AUTOSAR XML (schema 4.0)
standard types defined: float32, float64, sint16, sint32, sint8, uint16, uint32, uint8, void, boolean
package /ImplDataTypes
  8 x impl type, all with category=TYPE_REFERENCE, type-emitter=RTE:
    IOSensorPositionReadingType: implementation-data-type=uint8
    IOWeightSensorReadingType: implementation-data-type=uint16
    MultiStateBtnType: implementation-data-type=uint8
    SeatCtrlBtns: implementation-data-type=SeatCtrlData
    SeatModeBtn: implementation-data-type=uint8
    SensorPositionType: implementation-data-type=uint8
    SensorWeightType: implementation-data-type=uint8
    StepMotorStepType: implementation-data-type=void
package /MappingSets
  data type mapping set MappingSet: mode-request-type-map{implementation-data-type=uint8, mode-group=SeatCtrlMode}
package /PortInterfaces/ClientServer
  8 x client server interface:
    CsIf_HeightMotor
      operation Opr_HeightMotorMove
        arg Step: type=StepMotorStepType, direction=IN
    CsIf_IOGetSensorPosition
      operation Opr_IOGet
        arg position: type=IOSensorPositionReadingType, direction=OUT
    CsIf_IOGetSensorWeight
      operation Opr_IOGet
        arg weight: type=IOWeightSensorReadingType, direction=OUT
    CsIf_IOSetMotor
      operation Opr_IOSetBackward
      operation Opr_IOSetForward
    CsIf_InclineMotor
      operation Opr_InclineMotorMove
        arg Step: type=StepMotorStepType, direction=IN
    CsIf_PositionSensor
      operation Opr_GetPosition
        arg position: type=SensorPositionType, direction=OUT
    CsIf_SlideMotor
      operation Opr_SlideMotorMove
        arg Step: type=StepMotorStepType, direction=IN
    CsIf_WeightSensor
      operation Opr_GetWeight
        arg weight: type=SensorWeightType, direction=OUT
package /PortInterfaces/ModeSwitch
  mode switch interface MsIf_SeatCtrlMode
    mode group SeatCtrlMode: type=SeatCtrlMode
  mode declaration group SeatCtrlMode: category=ALPHABETIC_ORDER, initial-mode=INIT, on-transition-value=255
    mode AUTO
    mode INIT
    mode MANUAL
package /PortInterfaces/SenderReceiver
  sender receiver interface SrIf_SeatCtrlBtns
    data HeightBtnState: type=MultiStateBtnType
    data InclineBtnState: type=MultiStateBtnType
    data SlideBtnState: type=MultiStateBtnType
  sender receiver interface SrIf_SeatCtrlData
    data Height: type=uint8
    data Incline: type=uint8
    data Slide: type=uint8
  sender receiver interface SrIf_SeatModeBtn
    data DE_SeatModeBtn: type=SeatModeBtn
package /SoftwareComponents
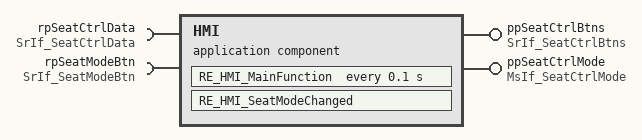
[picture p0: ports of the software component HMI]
  application sw component type HMI
    provide port ppSeatCtrlBtns: provided-interface=SrIf_SeatCtrlBtns
    provide port ppSeatCtrlMode: provided-interface=MsIf_SeatCtrlMode
    require port rpSeatCtrlData: required-interface=SrIf_SeatCtrlData
    require port rpSeatModeBtn: required-interface=SrIf_SeatModeBtn
    behavior Ibhv_HMI: data-type-mapping=MappingSet, handle-termination-and-restart=NO-SUPPORT
      data received event DRE_rpSeatModeBtn_DE_SeatModeBtn: start-on-event=RE_HMI_SeatModeChanged, data=rpSeatModeBtn.DE_SeatModeBtn
      timing event TE_RE_HMI_MainFunction_100ms: start-on-event=RE_HMI_MainFunction, period=0.1
      runnable RE_HMI_MainFunction
        data-receive-point-by-arguments:
          access DRP_rpSeatCtrlData_Height: accessed-variable=rpSeatCtrlData.Height
          access DRP_rpSeatCtrlData_Incline: accessed-variable=rpSeatCtrlData.Incline
          access DRP_rpSeatCtrlData_Slide: accessed-variable=rpSeatCtrlData.Slide
        data-send-points:
          access DSP_ppSeatCtrlBtns_HeightBtnState: accessed-variable=ppSeatCtrlBtns.HeightBtnState
          access DSP_ppSeatCtrlBtns_InclineBtnState: accessed-variable=ppSeatCtrlBtns.InclineBtnState
          access DSP_ppSeatCtrlBtns_SlideBtnState: accessed-variable=ppSeatCtrlBtns.SlideBtnState
      runnable RE_HMI_SeatModeChanged
        data-receive-point-by-arguments:
          access DRP_rpSeatModeBtn_DE_SeatModeBtn: accessed-variable=rpSeatModeBtn.DE_SeatModeBtn
        mode switch point MSP_ppSeatCtrlMode_ppSeatCtrlMode: mode-group=ppSeatCtrlMode.SeatCtrlMode
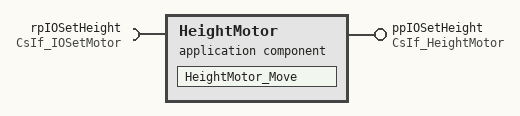
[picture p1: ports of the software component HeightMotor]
  application sw component type HeightMotor
    provide port ppIOSetHeight: provided-interface=CsIf_HeightMotor
    require port rpIOSetHeight: required-interface=CsIf_IOSetMotor
    behavior Ibhv_HeightMotor: data-type-mapping=MappingSet, handle-termination-and-restart=NO-SUPPORT
      operation invoked event OIE_ppIOSetHeight_Opr_HeightMotorMove: start-on-event=HeightMotor_Move, operation=ppIOSetHeight.Opr_HeightMotorMove
      runnable HeightMotor_Move
        sync call SCP_rpIOSetHeight_Opr_IOSetBackward: operation=rpIOSetHeight.Opr_IOSetBackward, timeout=0.0
        sync call SCP_rpIOSetHeight_Opr_IOSetForward: operation=rpIOSetHeight.Opr_IOSetForward, timeout=0.0
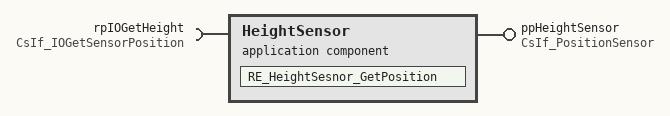
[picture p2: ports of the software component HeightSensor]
  application sw component type HeightSensor
    provide port ppHeightSensor: provided-interface=CsIf_PositionSensor
    require port rpIOGetHeight: required-interface=CsIf_IOGetSensorPosition
    behavior Ibhv_HeightSensor: data-type-mapping=MappingSet, handle-termination-and-restart=NO-SUPPORT
      operation invoked event OIE_ppHeightSensor_Opr_GetPosition: start-on-event=RE_HeightSesnor_GetPosition, operation=ppHeightSensor.Opr_GetPosition
      runnable RE_HeightSesnor_GetPosition
        sync call SCP_rpIOGetHeight_Opr_IOGet: operation=rpIOGetHeight.Opr_IOGet, timeout=0.0
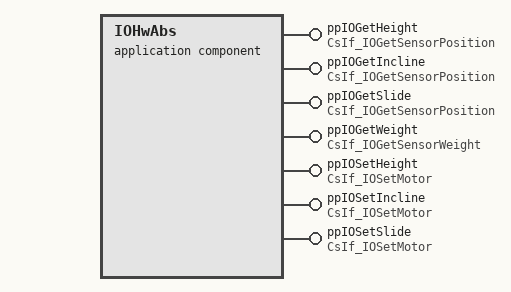
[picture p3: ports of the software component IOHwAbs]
  application sw component type IOHwAbs
    7 x provide port:
      ppIOGetHeight: provided-interface=CsIf_IOGetSensorPosition
      ppIOGetIncline: provided-interface=CsIf_IOGetSensorPosition
      ppIOGetSlide: provided-interface=CsIf_IOGetSensorPosition
      ppIOGetWeight: provided-interface=CsIf_IOGetSensorWeight
      ppIOSetHeight: provided-interface=CsIf_IOSetMotor
      ppIOSetIncline: provided-interface=CsIf_IOSetMotor
      ppIOSetSlide: provided-interface=CsIf_IOSetMotor
    behavior Ibhv_IOHwAbs: data-type-mapping=MappingSet, handle-termination-and-restart=NO-SUPPORT
      10 x operation invoked event:
        OIE_ppIOGetHeight_Opr_IOGet: start-on-event=RE_IOHwAbs_ECUGet_Height, operation=ppIOGetHeight.Opr_IOGet
        OIE_ppIOGetIncline_Opr_IOGet: start-on-event=RE_IOHwAbs_ECUGet_Incline, operation=ppIOGetIncline.Opr_IOGet
        OIE_ppIOGetSlide_Opr_IOGet: start-on-event=RE_IOHwAbs_ECUGet_Slide, operation=ppIOGetSlide.Opr_IOGet
        OIE_ppIOGetWeight_Opr_IOGet: start-on-event=RE_IOHwAbs_ECUGet_Weight, operation=ppIOGetWeight.Opr_IOGet
        OIE_ppIOSetHeight_Opr_IOSetBackward: start-on-event=RE_IOHwAbs_ECUSetBackward_Height, operation=ppIOSetHeight.Opr_IOSetBackward
        OIE_ppIOSetHeight_Opr_IOSetForward: start-on-event=RE_IOHwAbs_ECUSetForward_Height, operation=ppIOSetHeight.Opr_IOSetForward
        OIE_ppIOSetIncline_Opr_IOSetBackward: start-on-event=RE_IOHwAbs_ECUSetBackward_Incline, operation=ppIOSetIncline.Opr_IOSetBackward
        OIE_ppIOSetIncline_Opr_IOSetForward: start-on-event=RE_IOHwAbs_ECUSetForward_Incline, operation=ppIOSetIncline.Opr_IOSetForward
        OIE_ppIOSetSlide_Opr_IOSetBackward: start-on-event=RE_IOHwAbs_ECUSetBackward_Slide, operation=ppIOSetSlide.Opr_IOSetBackward
        OIE_ppIOSetSlide_Opr_IOSetForward: start-on-event=RE_IOHwAbs_ECUSetForward_Slide, operation=ppIOSetSlide.Opr_IOSetForward
      10 x runnable:
        RE_IOHwAbs_ECUGet_Height
        RE_IOHwAbs_ECUGet_Incline
        RE_IOHwAbs_ECUGet_Slide
        RE_IOHwAbs_ECUGet_Weight
        RE_IOHwAbs_ECUSetBackward_Height
        RE_IOHwAbs_ECUSetBackward_Incline
        RE_IOHwAbs_ECUSetBackward_Slide
        RE_IOHwAbs_ECUSetForward_Height
        RE_IOHwAbs_ECUSetForward_Incline
        RE_IOHwAbs_ECUSetForward_Slide
  10 x swc implementation, all with programming-language=C, sw-version=1.0.0, vendor-id=255:
    Impl_HMI: behavior=Ibhv_HMI
      code-descriptors:
        code Code: artifact-descriptors=autosar-engineering-object={short-label=SWC.c, category=SWSRC}
      resource consumption ResourceConsumption
    Impl_HeightMotor: behavior=Ibhv_HeightMotor
      code-descriptors:
        code Code: artifact-descriptors=autosar-engineering-object={short-label=SWC.c, category=SWSRC}
      resource consumption ResourceConsumption
    Impl_HeightSensor: behavior=Ibhv_HeightSensor
      code-descriptors:
        code Code: artifact-descriptors=autosar-engineering-object={short-label=SWC.c, category=SWSRC}
      resource consumption ResourceConsumption
    Impl_IOHwAbs: behavior=Ibhv_IOHwAbs
      code-descriptors:
        code Code: artifact-descriptors=autosar-engineering-object={short-label=SWC.c, category=SWSRC}
      resource consumption ResourceConsumption
    Impl_InclineMotor: behavior=Ibhv_InclineMotor
      code-descriptors:
        code Code: artifact-descriptors=autosar-engineering-object={short-label=SWC.c, category=SWSRC}
      resource consumption ResourceConsumption
    Impl_InclineSensor: behavior=Ibhv_InclineSensor
      code-descriptors:
        code Code: artifact-descriptors=autosar-engineering-object={short-label=SWC.c, category=SWSRC}
      resource consumption ResourceConsumption
    Impl_SeatManager: behavior=Ibhv_SeatManager
      code-descriptors:
        code Code: artifact-descriptors=autosar-engineering-object={short-label=SWC.c, category=SWSRC}
      resource consumption ResourceConsumption
    Impl_SlideMotor: behavior=Ibhv_SlideMotor
      code-descriptors:
        code Code: artifact-descriptors=autosar-engineering-object={short-label=SWC.c, category=SWSRC}
      resource consumption ResourceConsumption
    Impl_SlideSensor: behavior=Ibhv_SlideSensor
      code-descriptors:
        code Code: artifact-descriptors=autosar-engineering-object={short-label=SWC.c, category=SWSRC}
      resource consumption ResourceConsumption
    Impl_WeightSensor: behavior=Ibhv_WeightSensor
      code-descriptors:
        code Code: artifact-descriptors=autosar-engineering-object={short-label=SWC.c, category=SWSRC}
      resource consumption ResourceConsumption
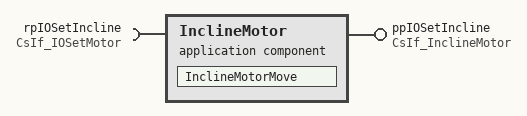
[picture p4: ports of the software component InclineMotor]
  application sw component type InclineMotor
    provide port ppIOSetIncline: provided-interface=CsIf_InclineMotor
    require port rpIOSetIncline: required-interface=CsIf_IOSetMotor
    behavior Ibhv_InclineMotor: data-type-mapping=MappingSet, handle-termination-and-restart=NO-SUPPORT
      operation invoked event OIE_ppIOSetIncline_Opr_InclineMotorMove: start-on-event=InclineMotorMove, operation=ppIOSetIncline.Opr_InclineMotorMove
      runnable InclineMotorMove
        sync call SCP_rpIOSetIncline_Opr_IOSetBackward: operation=rpIOSetIncline.Opr_IOSetBackward, timeout=0.0
        sync call SCP_rpIOSetIncline_Opr_IOSetForward: operation=rpIOSetIncline.Opr_IOSetForward, timeout=0.0
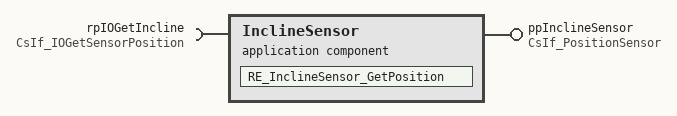
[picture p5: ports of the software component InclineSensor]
  application sw component type InclineSensor
    provide port ppInclineSensor: provided-interface=CsIf_PositionSensor
    require port rpIOGetIncline: required-interface=CsIf_IOGetSensorPosition
    behavior Ibhv_InclineSensor: data-type-mapping=MappingSet, handle-termination-and-restart=NO-SUPPORT
      operation invoked event OIE_ppInclineSensor_Opr_GetPosition: start-on-event=RE_InclineSensor_GetPosition, operation=ppInclineSensor.Opr_GetPosition
      runnable RE_InclineSensor_GetPosition
        sync call SCP_rpIOGetIncline_Opr_IOGet: operation=rpIOGetIncline.Opr_IOGet, timeout=0.0
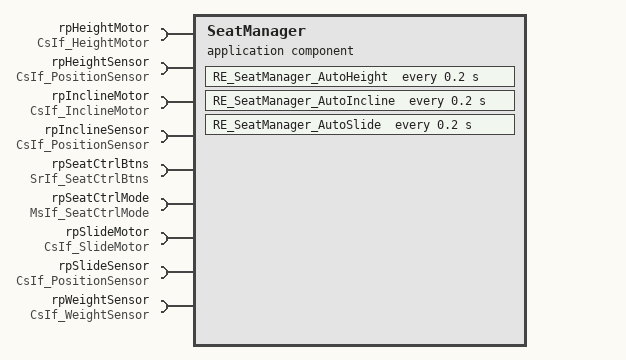
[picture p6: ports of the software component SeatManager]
  application sw component type SeatManager
    9 x require port:
      rpHeightMotor: required-interface=CsIf_HeightMotor
      rpHeightSensor: required-interface=CsIf_PositionSensor
      rpInclineMotor: required-interface=CsIf_InclineMotor
      rpInclineSensor: required-interface=CsIf_PositionSensor
      rpSeatCtrlBtns: required-interface=SrIf_SeatCtrlBtns
      rpSeatCtrlMode: required-interface=MsIf_SeatCtrlMode
      rpSlideMotor: required-interface=CsIf_SlideMotor
      rpSlideSensor: required-interface=CsIf_PositionSensor
      rpWeightSensor: required-interface=CsIf_WeightSensor
    behavior Ibhv_SeatManager: data-type-mapping=MappingSet, handle-termination-and-restart=NO-SUPPORT
      data received event DRE_rpSeatCtrlBtns_HeightBtnState: start-on-event=RE_SeatManger_SetHeight, data=rpSeatCtrlBtns.HeightBtnState
      data received event DRE_rpSeatCtrlBtns_InclineBtnState: start-on-event=RE_SeatManager_SetIncline, data=rpSeatCtrlBtns.InclineBtnState
      data received event DRE_rpSeatCtrlBtns_SlideBtnState: start-on-event=RE_SeatManager_SetSlide, data=rpSeatCtrlBtns.SlideBtnState
      timing event TE_RE_SeatManager_AutoHeight_200ms: start-on-event=RE_SeatManager_AutoHeight, period=0.2
      timing event TE_RE_SeatManager_AutoIncline_200ms: start-on-event=RE_SeatManager_AutoIncline, period=0.2
      timing event TE_RE_SeatManager_AutoSlide_200ms: start-on-event=RE_SeatManager_AutoSlide, period=0.2
      6 x runnable:
        RE_SeatManager_AutoHeight
          sync call SCP_rpHeightMotor_Opr_HeightMotorMove: operation=rpHeightMotor.Opr_HeightMotorMove, timeout=0.0
          sync call SCP_rpHeightSensor_Opr_GetPosition: operation=rpHeightSensor.Opr_GetPosition, timeout=0.0
          sync call SCP_rpWeightSensor_Opr_GetWeight: operation=rpWeightSensor.Opr_GetWeight, timeout=0.0
        RE_SeatManager_AutoIncline
          sync call SCP_rpInclineMotor_Opr_InclineMotorMove: operation=rpInclineMotor.Opr_InclineMotorMove, timeout=0.0
          sync call SCP_rpInclineSensor_Opr_GetPosition: operation=rpInclineSensor.Opr_GetPosition, timeout=0.0
          sync call SCP_rpWeightSensor_Opr_GetWeight: operation=rpWeightSensor.Opr_GetWeight, timeout=0.0
        RE_SeatManager_AutoSlide
          sync call SCP_rpSlideMotor_Opr_SlideMotorMove: operation=rpSlideMotor.Opr_SlideMotorMove, timeout=0.0
          sync call SCP_rpSlideSensor_Opr_GetPosition: operation=rpSlideSensor.Opr_GetPosition, timeout=0.0
          sync call SCP_rpWeightSensor_Opr_GetWeight: operation=rpWeightSensor.Opr_GetWeight, timeout=0.0
        RE_SeatManager_SetIncline
          data-receive-point-by-arguments:
            access DRP_rpSeatCtrlBtns_InclineBtnState: accessed-variable=rpSeatCtrlBtns.InclineBtnState
          sync call SCP_rpInclineMotor_Opr_InclineMotorMove: operation=rpInclineMotor.Opr_InclineMotorMove, timeout=0.0
        RE_SeatManager_SetSlide
          data-receive-point-by-arguments:
            access DRP_rpSeatCtrlBtns_SlideBtnState: accessed-variable=rpSeatCtrlBtns.SlideBtnState
          sync call SCP_rpSlideMotor_Opr_SlideMotorMove: operation=rpSlideMotor.Opr_SlideMotorMove, timeout=0.0
        RE_SeatManger_SetHeight
          data-receive-point-by-arguments:
            access DRP_rpSeatCtrlBtns_HeightBtnState: accessed-variable=rpSeatCtrlBtns.HeightBtnState
          sync call SCP_rpHeightMotor_Opr_HeightMotorMove: operation=rpHeightMotor.Opr_HeightMotorMove, timeout=0.0
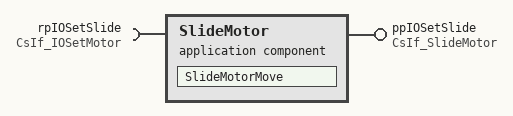
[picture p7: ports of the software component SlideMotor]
  application sw component type SlideMotor
    provide port ppIOSetSlide: provided-interface=CsIf_SlideMotor
    require port rpIOSetSlide: required-interface=CsIf_IOSetMotor
    behavior Ibhv_SlideMotor: data-type-mapping=MappingSet, handle-termination-and-restart=NO-SUPPORT
      operation invoked event OIE_ppIOSetSlide_Opr_SlideMotorMove: start-on-event=SlideMotorMove, operation=ppIOSetSlide.Opr_SlideMotorMove
      runnable SlideMotorMove
        sync call SCP_rpIOSetSlide_Opr_IOSetBackward: operation=rpIOSetSlide.Opr_IOSetBackward, timeout=0.0
        sync call SCP_rpIOSetSlide_Opr_IOSetForward: operation=rpIOSetSlide.Opr_IOSetForward, timeout=0.0
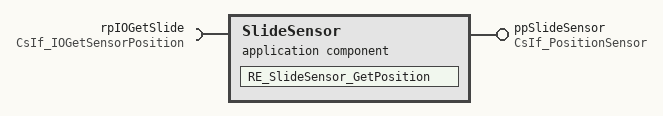
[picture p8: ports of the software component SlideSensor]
  application sw component type SlideSensor
    provide port ppSlideSensor: provided-interface=CsIf_PositionSensor
    require port rpIOGetSlide: required-interface=CsIf_IOGetSensorPosition
    behavior Ibhv_SlideSensor: data-type-mapping=MappingSet, handle-termination-and-restart=NO-SUPPORT
      operation invoked event OIE_ppSlideSensor_Opr_GetPosition: start-on-event=RE_SlideSensor_GetPosition, operation=ppSlideSensor.Opr_GetPosition
      runnable RE_SlideSensor_GetPosition
        sync call SCP_rpIOGetSlide_Opr_IOGet: operation=rpIOGetSlide.Opr_IOGet, timeout=0.0
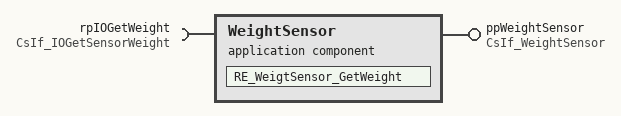
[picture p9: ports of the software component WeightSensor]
  application sw component type WeightSensor
    provide port ppWeightSensor: provided-interface=CsIf_WeightSensor
    require port rpIOGetWeight: required-interface=CsIf_IOGetSensorWeight
    behavior Ibhv_WeightSensor: data-type-mapping=MappingSet, handle-termination-and-restart=NO-SUPPORT
      operation invoked event OIE_ppWeightSensor_Opr_GetWeight: start-on-event=RE_WeigtSensor_GetWeight, operation=ppWeightSensor.Opr_GetWeight
      runnable RE_WeigtSensor_GetWeight
        sync call SCP_rpIOGetWeight_Opr_IOGet: operation=rpIOGetWeight.Opr_IOGet, timeout=0.0
package /Compositions
  composition sw component type Task2_RTEComposition
    10 x component:
      HMI: type=HMI
      HeightMotor: type=HeightMotor
      HeightSensor: type=HeightSensor
      IOHwAbs: type=IOHwAbs
      InclineMotor: type=InclineMotor
      InclineSensor: type=InclineSensor
      SeatManager: type=SeatManager
      SlideMotor: type=SlideMotor
      SlideSensor: type=SlideSensor
      WeightSensor: type=WeightSensor
    connect HMI.ppSeatCtrlBtns -> SeatManager.rpSeatCtrlBtns
    connect HMI.ppSeatCtrlMode -> SeatManager.rpSeatCtrlMode
    connect HeightMotor.ppIOSetHeight -> SeatManager.rpHeightMotor
    connect HeightSensor.ppHeightSensor -> SeatManager.rpHeightSensor
    connect IOHwAbs.ppIOGetHeight -> HeightSensor.rpIOGetHeight
    connect IOHwAbs.ppIOGetIncline -> InclineSensor.rpIOGetIncline
    connect IOHwAbs.ppIOGetSlide -> SlideSensor.rpIOGetSlide
    connect IOHwAbs.ppIOGetWeight -> WeightSensor.rpIOGetWeight
    connect IOHwAbs.ppIOSetHeight -> HeightMotor.rpIOSetHeight
    connect IOHwAbs.ppIOSetIncline -> InclineMotor.rpIOSetIncline
    connect IOHwAbs.ppIOSetSlide -> SlideMotor.rpIOSetSlide
    connect InclineMotor.ppIOSetIncline -> SeatManager.rpInclineMotor
    connect InclineSensor.ppInclineSensor -> SeatManager.rpInclineSensor
    connect SlideMotor.ppIOSetSlide -> SeatManager.rpSlideMotor
    connect SlideSensor.ppSlideSensor -> SeatManager.rpSlideSensor
    connect WeightSensor.ppWeightSensor -> SeatManager.rpWeightSensor
